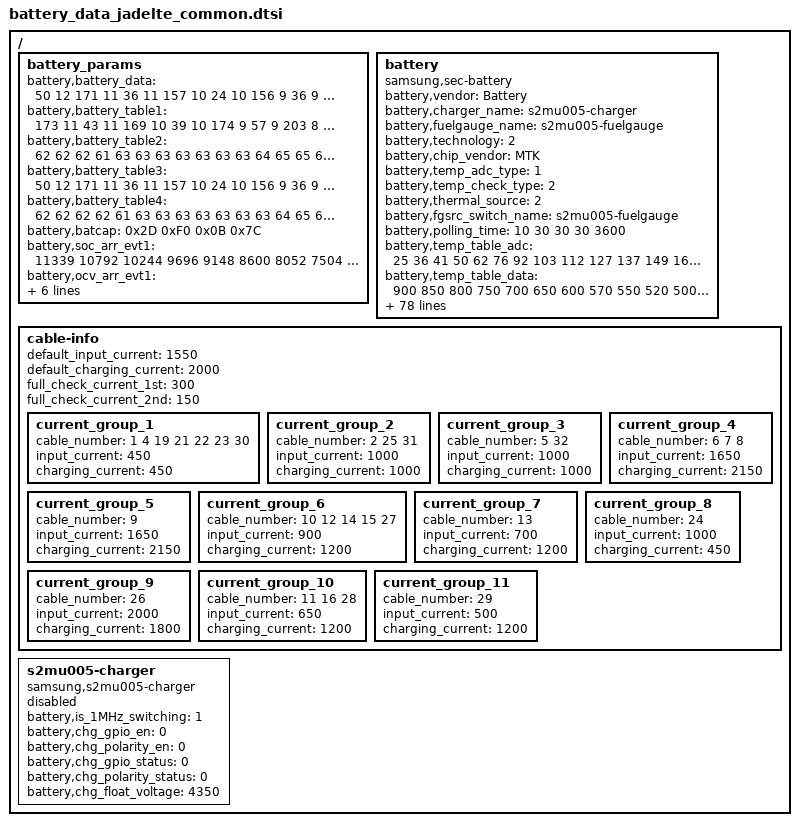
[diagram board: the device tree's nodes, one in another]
/*
 * JADELTE Battery parameters device tree file for board IDs 04 and higher
 *
 * Copyright (C) 2017 Samsung Electronics, Inc.
 *
 * This program is free software; you can redistribute it and/or
 * modify it under the terms of the GNU General Public License
 * as published by the Free Software Foundation; either version 2
 * of the License, or (at your option) any later version.
 *
 * This program is distributed in the hope that it will be useful,
 * but WITHOUT ANY WARRANTY; without even the implied warranty of
 * MERCHANTABILITY or FITNESS FOR A PARTICULAR PURPOSE.  See the
 * GNU General Public License for more details.
 *
 * You should have received a copy of the GNU General Public License
 * along with this program. If not, see <http://www.gnu.org/licenses/>.
 *
 */

/ {
	battery_params {
			battery,battery_data =
			<
				/***** battery data for 4.35 *****/
				/* battery,battery_table3 */
				50 12 171 11 36 11 157 10 24 10
				156 9 36 9 179 8 74 8 231 7
				131 7 26 7 208 6 156 6 115 6
				83 6 51 6 8 6 215 5 148 5
				123 5 130 3 49 9 192 8 80 8
				224 7 111 7 255 6 143 6 30 6
				174 5 62 5 205 4 93 4 237 3
				124 3 12 3 156 2 43 2 187 1
				75 1 218 0 106 0 249 15

				/* battery,battery_table4 */
				62 62 62 62 61 63 63 63 63 63
				63 63 64 65 65 66 67 67 69 71
				76 154

				/* battery,batcap */
				0x2D 0xF0 0x0B 0x7C /* [0x0F] [0x0E] [0x11] [0x10] */

				/* battery,accum */ 
				0xF5 0x7 /* [0x44] [0x45] */

				/* battery,soc_arr_val */
				11489 10940 10391 9843 9294 8746 8197 7648 7100 6551 6002 5454 4905 4357 3808 3260 2711 2162 1613 1065 517 (-32)
				/* battery,ocv_arr_val */
				45243 44585 43926 43269 42619 42011 41426 40876 40359 39879 39389 38876 38514 38262 38064 37905 37749 37541 37299 36975 36852 34387

				/***** battery data for 4.33 *****/
				/* battery,battery_table3 */
				173 11 43 11 169 10 39 10 174 9
				58 9 203 8 101 8 0 8 169 7
				58 7 230 6 176 6 133 6 98 6
				68 6 34 6 245 5 192 5 137 5
				243 4 128 1 234 8 123 8 13 8
				158 7 48 7 194 6 83 6 229 5
				118 5 8 5 153 4 43 4 189 3
				78 3 224 2 113 2 3 2 148 1
				38 1 183 0 73 0 219 15

				/* battery,battery_table4 */
				62 62 62 61 63 63 63 63 63 63
				63 64 65 65 66 67 67 69 71 76
				90 132

				/* battery,batcap */
				0x2B 0x54 0x0A 0xD5 /* [0x0F] [0x0E] [0x11] [0x10] */
				/* battery,accum */
				0xF5 0x7 /* [0x44] [0x45] */

				/* battery,soc_arr_val */
				11142 10603 10064 9524 8985 8446 7907 7367 6828 6289 5749 5210 4671 4131 3592 3053 2514 1974 1435 896 356 (-183)
				/* battery,ocv_arr_val */
				44593 43959 43324 42691 42101 41531 40989 40492 40001 39575 39034 38625 38358 38148 37977 37833 37666 37446 37186 36919 36186 31873

				/***** battery data for 4.31 *****/
				/* battery,battery_table3 */
				173 11 43 11 169 10 39 10 174 9
				58 9 203 8 101 8 0 8 169 7
				58 7 230 6 176 6 133 6 98 6
				68 6 34 6 245 5 192 5 137 5
				243 4 128 1 17 9 161 8 49 8
				192 7 80 7 224 6 111 6 255 5
				143 5 30 5 174 4 61 4 205 3
				93 3 236 2 124 2 12 2 155 1
				43 1 187 0 74 0 218 15

				/* battery,battery_table4 */
				62 62 62 61 63 63 63 63 63 63
				63 64 65 65 66 67 67 69 71 76
				90 132

				/* battery,batcap */
				0x2A 0x94 0x0A 0xA5 /* [0x0F] [0x0E] [0x11] [0x10] */
				/* battery,accum */
				0xF5 0x7 /* [0x44] [0x45] */

				/* battery,soc_arr_val */
				11335 10786 10237 9689 9140 8592 8043 7494 6946 6397 5849 5300 4751 4203 3654 3106 2557 2008 1460 911 363 (-185)
				/* battery,ocv_arr_val */
				44593 43959 43324 42691 42100 41531 40990 40492 40001 39575 39034 38625 38358 38148 37977 37833 37666 37446 37186 36919 36186 31873

				/***** battery data for 4.29 *****/
				/* battery,battery_table3 */
				173 11 43 11 169 10 39 10 174 9
				57 9 203 8 101 8 0 8 169 7
				58 7 230 6 176 6 133 6 98 6
				68 6 34 6 245 5 192 5 137 5
				242 4 128 1 57 9 199 8 85 8
				226 7 112 7 254 6 139 6 25 6
				167 5 53 5 194 4 80 4 222 3
				107 3 249 2 135 2 21 2 162 1
				48 1 190 0 75 0 217 15

				/* battery,battery_table4 */
				62 62 62 61 63 63 63 63 63 63
				63 64 65 65 66 67 67 69 71 76
				90 132

				/* battery,batcap */
				0x29 0xE4 0x0A 0x79 /* [0x0F] [0x0E] [0x11] [0x10] */
				/* battery,accum */
				0xF5 0x7 /* [0x44] [0x45] */

				/* battery,soc_arr_val */
				11530 10972 10414 9856 9298 8740 8181 7623 7065 6506 5949 5391 4833 4275 3716 3159 2601 2042 1484 926 368 (-190)
				/* battery,ocv_arr_val */
				44593 43959 43324 42691 42100 41529 40990 40491 40001 39574 39034 38625 38358 38148 37977 37833 37666 37446 37186 36918 36182 31873

				/***** battery data for 4.24 *****/
				/* battery,battery_table3 */
				173 11 43 11 169 10 39 10 174 9
				58 9 203 8 101 8 0 8 169 7
				58 7 230 6 175 6 132 6 98 6
				68 6 34 6 245 5 192 5 137 5
				242 4 128 1 171 9 51 9 187 8
				67 8 203 7 84 7 220 6 100 6
				236 5 116 5 253 4 133 4 13 4
				149 3 30 3 166 2 46 2 182 1
				63 1 199 0 79 0 215 15

				/* battery,battery_table4 */
				62 62 62 61 63 63 63 63 63 63
				63 64 65 65 66 67 67 69 71 76
				90 132

				/* battery,batcap */
				0x26 0xFC 0x09 0xBF /* [0x0F] [0x0E] [0x11] [0x10] */
				/* battery,accum */
				0xF5 0x7 /* [0x44] [0x45] */

				/* battery,soc_arr_val */
				12083 11498 10913 10328 9743 9159 8574 7989 7403 6818 6233 5649 5064 4480 3895 3310 2725 2140 1555 971 386 (-199)
				/* battery,ocv_arr_val */
				44593 43959 43324 42690 42100 41531 40989 40491 40000 39574 39034 38625 38357 38147 37977 37833 37666 37445 37186 36918 36184 31873
			>;
			battery,battery_table1 = <
					173 11 43 11 169 10 39 10 174 9
					57 9 203 8 101 8 0 8 169 7
					58 7 230 6 175 6 132 6 98 6
					68 6 34 6 245 5 192 5 137 5
					243 4 128 1 18 9 162 8 50 8
					194 7 81 7 225 6 113 6 1 6
					145 5 32 5 176 4 64 4 208 3
					95 3 239 2 127 2 15 2 158 1
					46 1 190 0 78 0 222 15
					>;

			battery,battery_table2 = <
					62 62 62 61 63 63 63 63 63 63
					63 64 65 65 66 67 67 69 71 76
					90 132
					>;

			battery,battery_table3 = <
					50 12 171 11 36 11 157 10 24 10 
					156 9 36 9 179 8 74 8 231 7
					131 7 26 7 208 6 156 6 115 6
					83 6 51 6 8 6 215 5 148 5
					123 5 130 3 49 9 192 8 80 8
					224 7 111 7 255 6 143 6 30 6
					174 5 62 5 205 4 93 4 237 3
					124 3 12 3 156 2 43 2 187 1
					75 1 218 0 106 0 249 15
					>;

			battery,battery_table4 = <
					62 62 62 62 61 63 63 63 63 63
					63 63 64 65 65 66 67 67 69 71
					76 154
					>;

			battery,batcap = <0x2D 0xF0 0x0B 0x7C>; /* [0x0F] [0x0E] [0x11] [0x10] */

			battery,soc_arr_evt1 = <
						11339 10792 10244 9696 9148 8600 8052 7504 6956 6408
						5860 5312 4764 4216 3668 3120 2572 2024 1476 927
						380 (-168)
						>;
			battery,ocv_arr_evt1 = <
						44593 43959 43324 42691 42100 41529 40989 40491 40001 39574
						39034 38625 38357 38147 37977 37833 37666 37446 37186 36919
						36186 31873
						>;

			battery,soc_arr_evt2 = <
						11489 10940 10391 9843 9294 8746 8197 7648 7100 6551
						6002 5454 4905 4357 3808 3260 2711 2162 1613 1065
						517 (-32)
						>;
			battery,ocv_arr_evt2 = <
						45243 44585 43926 43269 42619 42011 41426 40876 40359 39879
						39389 38876 38514 38262 38064 37905 37749 37541 37299 36975
						36852 34387
						>;

			battery,FG_Accumulative_rate_evt2 = <0xF5 0x7>; /* 0x44 0x45 */
	};

	battery {
		status = "okay";
		compatible = "samsung,sec-battery";

		pinctrl-names = "default";

		battery,vendor = "Battery";
		battery,charger_name = "s2mu005-charger";
		battery,fuelgauge_name = "s2mu005-fuelgauge";
		battery,technology = <2>; /* POWER_SUPPLY_TECHNOLOGY_LION */

		battery,chip_vendor = "MTK";
		battery,temp_adc_type = <1>; /* SEC_BATTERY_ADC_TYPE_AP */

		battery,temp_check_type = <2>; /* SEC_BATTERY_TEMP_CHECK_TEMP */

		battery,thermal_source = <2>; /* SEC_BATTERY_THERMAL_SOURCE_ADC */

		battery,fgsrc_switch_name = "s2mu005-fuelgauge";

		battery,polling_time = <10 30 30 30 3600>;

		battery,temp_table_adc = <
					25 36 41 50 62 76 92 103 112 127
					137 149 168 182 197 220 238 257	301
					365 409	441 475	530 570	633 677	745
					793 864	907 986	1117 1241 1358 1515
					>;

		battery,temp_table_data = <
					900 850 800 750 700 650 600 570
					550 520 500 480 450 430 410 380
					360 340 300 250 220 200 180 150
					130 100 80 50 30 0 (-20) (-50) (-100) (-150) (-200) (-300)
					>;

		battery,adc_check_count = <5>;

		battery,cable_check_type = <4>; /* SEC_BATTERY_CABLE_CHECK_PSY */
		battery,cable_source_type = <1>; /* SEC_BATTERY_CABLE_SOURCE_EXTERNAL */
		battery,polling_type = <1>; /* SEC_BATTERY_MONITOR_ALARM */
		battery,monitor_initial_count = <0>;

		battery,battery_check_type = <0>; /* SEC_BATTERY_CHECK_NONE */
		battery,check_count = <0>;
		battery,check_adc_max = <1440>;
		battery,check_adc_min = <0>;

		battery,ovp_uvlo_check_type = <3>; /* SEC_BATTERY_OVP_UVLO_CHGPOLLING */

		battery,temp_check_count = <1>;
		battery,temp_highlimit_threshold_event = <800>;
		battery,temp_highlimit_recovery_event = <750>;
		battery,temp_high_threshold_event = <500>;
		battery,temp_high_recovery_event = <450>;
		battery,temp_low_threshold_event = <(0)>;
		battery,temp_low_recovery_event = <50>;
		battery,temp_highlimit_threshold_normal = <800>;
		battery,temp_highlimit_recovery_normal = <750>;
		battery,temp_high_threshold_normal = <500>;
		battery,temp_high_recovery_normal = <450>;
		battery,temp_low_threshold_normal = <(0)>;
		battery,temp_low_recovery_normal = <50>;
		battery,temp_highlimit_threshold_lpm = <800>;
		battery,temp_highlimit_recovery_lpm = <750>;
		battery,temp_high_threshold_lpm = <500>;
		battery,temp_high_recovery_lpm = <450>;
		battery,temp_low_threshold_lpm = <(0)>;
		battery,temp_low_recovery_lpm = <50>;
		battery,wpc_high_threshold_normal = <450>;
		battery,wpc_high_recovery_normal = <400>;
		battery,wpc_low_threshold_normal = <(0)>;
		battery,wpc_low_recovery_normal = <50>;
		battery,full_check_type = <2>; /* SEC_BATTERY_FULLCHARGED_FG_CURRENT */
		battery,full_check_type_2nd = <2>; /* SEC_BATTERY_FULLCHARGED_FG_CURRENT */
		battery,full_check_count = <1>;
		battery,chg_gpio_full_check = <0>;
		battery,chg_polarity_full_check = <1>;

		/* SEC_BATTERY_FULL_CONDITION_SOC |
		   SEC_BATTERY_FULL_CONDITION_NOTIMEFULL |
		   SEC_BATTERY_FULL_CONDITION_VCELL |
		   SEC_BATTERY_FULL_CONDITION_NOSLEEPINFULL */
		battery,full_condition_type = <15>;
		battery,full_condition_soc = <93>;
		battery,full_condition_vcell = <4250>;

		battery,recharge_check_count = <2>;
		battery,recharge_condition_type = <4>; /* SEC_BATTERY_RECHARGE_CONDITION_VCELL */
		battery,recharge_condition_soc = <98>;
		battery,recharge_condition_vcell = <4280>;

		battery,charging_total_time = <14400>;
		battery,hv_charging_total_time = <10800>;
		battery,normal_charging_total_time = <18000>;
		battery,usb_charging_total_time = <36000>;
		battery,recharging_total_time = <5400>;
		battery,charging_reset_time = <0>;

		battery,chg_float_voltage = <4350>;

		battery,swelling_high_temp_block = <410>;
		battery,swelling_high_temp_recov = <390>;
		battery,swelling_low_temp_block_1st = <150>;
		battery,swelling_low_temp_recov_1st = <200>;
		battery,swelling_low_temp_block_2nd = <50>;
		battery,swelling_low_temp_recov_2nd = <100>;

		battery,swelling_low_temp_current = <900>;	/* 0.3C */
		battery,swelling_low_temp_topoff = <150>;	/* 0.05C */
		battery,swelling_high_temp_current = <1350>;	/* 0.45C */
		battery,swelling_high_temp_topoff = <150>;	/* 0.05C */
		battery,swelling_wc_high_temp_current = <900>;	/* 0.3C */
		battery,swelling_wc_low_temp_current = <900>;	/* 0.3C */

		battery,swelling_drop_float_voltage = <4150>;
		battery,swelling_high_rechg_voltage = <4000>;
		battery,swelling_low_rechg_voltage = <4000>;

		battery,siop_event_check_type = <1>;
		battery,siop_call_cv_current = <330>;
		battery,siop_call_cc_current = <330>;

		battery,siop_input_limit_current = <1200>;
		battery,siop_charging_limit_current = <1000>;

		battery,standard_curr = <1602>; /* TA standard current or AFC current */
		battery,expired_time = <18000>;
		battery,recharging_expired_time = <5400>;

		/* S2MU005 specific error rate calculation (max positive): Float Voltage * (BUCK VSYS sensing, 5%) * (FG ADC, 0.5%)*/
		/* S2MU005 specific error rate calculation (max positive): Float Voltage * 1.05 * 1.005*/
		battery,cisd_max_voltage_thr = <4590>; /* battery ovp detection voltage */

		/* cycle, chg_float_voltage, recharge_condition_vcell, full_condition_vcell, full_condition_soc */
		battery,age_data = <0 4350 4280 4250 93	/*4.35*/
				200 4330 4260 4230 92	/*4.33*/
				250 4310 4240 4210 91	/*4.31*/
				300 4290 4220 4190 90	/*4.29*/
				1000 4240 4170 4140 89	/*4.24*/
				>;
	};

/* sec_battery_cable
 *   0	UNKNOWN,
 *   1	NONE,
 *   2	PREPARE_TA,
 *   3	TA,
 *   4	USB,
 *   5	USB_CDP,
 *   6	9V_TA,
 *   7	9V_ERR,
 *   8	9V_UNKNOWN,
 *   9	12V_TA,
 *  10	WIRELESS,
 *  11	HV_WIRELESS,
 *  12	PMA_WIRELESS,
 *  13	WIRELESS_PACK,
 *  14	WIRELESS_PACK_TA,
 *  15	WIRELESS_STAND,
 *  16	WIRELESS_HV_STAND,
 *  17	QC20,
 *  18	QC30,
 *  19	PDIC,
 *  20	UARTOFF,
 *  21	OTG,
 *  22	LAN_HUB,
 *  23	POWER_SHARING,
 *  24	HMT_CONNECTED,
 *  25	HMT_CHARGE,
 *  26	HV_TA_CHG_LIMIT,
 *  27	WIRELESS_VEHICLE,
 *  28	WIRELESS_HV_VEHICLE,
 *  29	PREPARE_WIRELESS_HV,
 *  30	TIMEOUT,
 *  31	SMART_OTG,
 *  32	SMART_NOTG,
 *  33	CABLE_MAX,
*/
	cable-info {
		default_input_current = <1550>;
		default_charging_current = <2000>;
		full_check_current_1st = <300>;
		full_check_current_2nd = <150>;

		current_group_1 {
			cable_number = <1 4 19 21 22 23 30>;
			input_current = <450>;
			charging_current = <450>;
		};
		current_group_2 {
			cable_number = <2 25 31>;
			input_current = <1000>;
			charging_current = <1000>;
		};
		current_group_3 {
			cable_number = <5 32>;
			input_current = <1000>;
			charging_current = <1000>;
		};
		current_group_4 {
			cable_number = <6 7 8>;
			input_current = <1650>;
			charging_current = <2150>;
		};
		current_group_5 {
			cable_number = <9>;
			input_current = <1650>;
			charging_current = <2150>;
		};
		current_group_6 {
			cable_number = <10 12 14 15 27>;
			input_current = <900>;
			charging_current = <1200>;
		};
		current_group_7 {
			cable_number = <13>;
			input_current = <700>;
			charging_current = <1200>;
		};
		current_group_8 {
			cable_number = <24>;
			input_current = <1000>;
			charging_current = <450>;
		};
		current_group_9 {
			cable_number = <26>;
			input_current = <2000>;
			charging_current = <1800>;
		};
		current_group_10 {
			cable_number = <11 16 28>;
			input_current = <650>;
			charging_current = <1200>;
		};
		current_group_11 {
			cable_number = <29>;
			input_current = <500>;
			charging_current = <1200>;
		};
	};

	s2mu005-charger {
		status = "disable";
		compatible = "samsung,s2mu005-charger";
		battery,is_1MHz_switching = <1>;
		battery,chg_gpio_en = <0>;
		battery,chg_polarity_en = <0>;
		battery,chg_gpio_status = <0>;
		battery,chg_polarity_status = <0>;
		battery,chg_float_voltage = <4350>;
	};
};
